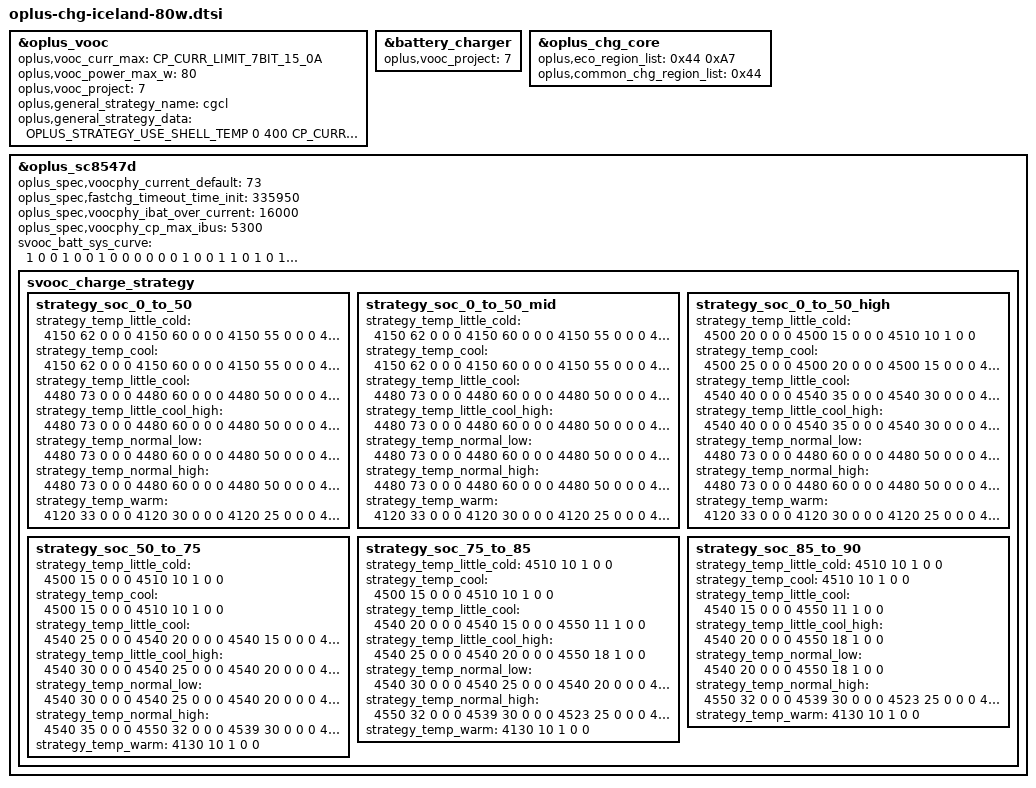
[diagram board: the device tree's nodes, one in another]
&oplus_vooc {
	oplus,vooc_curr_max = <CP_CURR_LIMIT_7BIT_15_0A>;
	oplus,vooc_power_max_w = <80>;
	oplus,vooc_project = <7>;
	oplus,general_strategy_name = "cgcl";
	oplus,general_strategy_data = < OPLUS_STRATEGY_USE_SHELL_TEMP
					0   400 CP_CURR_LIMIT_7BIT_15_0A 1 0
					390 410 CP_CURR_LIMIT_7BIT_7_0A 2 0
					400 420 CP_CURR_LIMIT_7BIT_5_0A 3 1
					410 430 CP_CURR_LIMIT_7BIT_4_0A 4 2
					420 440 CP_CURR_LIMIT_7BIT_3_0A 4 3 >;
};

&battery_charger {
	oplus,vooc_project = <7>;
};

&oplus_chg_core {
	oplus,eco_region_list = /bits/ 8 <0x44 /* EUEX */
					  0xA7 /* ROW */>;
	oplus,common_chg_region_list = /bits/ 8 <0x44 /* EUEX */>;
};

&oplus_sc8547d {
	oplus_spec,voocphy_current_default = <73>;
	oplus_spec,fastchg_timeout_time_init = <335950>;
	oplus_spec,voocphy_ibat_over_current = <16000>;
	oplus_spec,voocphy_cp_max_ibus = <5300>;

	svooc_batt_sys_curve = <1 0 0 1 0 0 1	// 7300mA
				0 0 0 0 0 0 1	// 3414mV
				0 0 1 1 0 1 0	// 2600mA
				1 1 1 1 1 1 0	// 4664mV
				0 0 0 1 0 1 1	// 1100mA
				1 1 1 1 1 1 0>;	// 4664mV

	svooc_charge_strategy {
		strategy_soc_0_to_50 { /* 0 ~ 20 */
			/* 0c ~ 5c */
			strategy_temp_little_cold =	<4150 62 0 0 0
							 4150 60 0 0 0
							 4150 55 0 0 0
							 4150 50 0 0 0
							 4150 45 0 0 0
							 4500 42 0 0 0
							 4500 40 0 0 0
							 4500 35 0 0 0
							 4500 30 0 0 0
							 4500 25 0 0 0
							 4500 20 0 0 0
							 4500 15 0 0 0
							 4510 10 1 0 0>;
			/* 5c ~ 12c */
			strategy_temp_cool =		<4150 62 0 0 0
							 4150 60 0 0 0
							 4150 55 0 0 0
							 4150 50 0 0 0
							 4150 45 0 0 0
							 4500 42 0 0 0
							 4500 40 0 0 0
							 4500 35 0 0 0
							 4500 30 0 0 0
							 4500 25 0 0 0
							 4500 20 0 0 0
							 4500 15 0 0 0
							 4510 10 1 0 0>;
			/* 12c ~ 16c */
			strategy_temp_little_cool =	<4480 73 0 0 0
							 4480 60 0 0 0
							 4480 50 0 0 0
							 4540 49 0 0 0
							 4540 45 0 0 0
							 4540 40 0 0 0
							 4540 35 0 0 0
							 4540 30 0 0 0
							 4540 25 0 0 0
							 4540 20 0 0 0
							 4540 15 0 0 0
							 4550 11 1 0 0>;
			/* 16c ~ 21c */
			strategy_temp_little_cool_high = <4480 73 0 0 0
							  4480 60 0 0 0
							  4480 50 0 0 0
							  4540 49 0 0 0
							  4540 45 0 0 0
							  4540 40 0 0 0
							  4540 35 0 0 0
							  4540 30 0 0 0
							  4540 25 0 0 0
							  4540 20 0 0 0
							  4550 18 1 0 0>;
			/* 21c ~ 35c */
			strategy_temp_normal_low =	<4480 73 0 0 0
							 4480 60 0 0 0
							 4480 50 0 0 0
							 4540 49 0 0 0
							 4540 45 0 0 0
							 4540 40 0 0 0
							 4540 35 0 0 0
							 4540 30 0 0 0
							 4540 25 0 0 0
							 4540 20 0 0 0
							 4550 18 1 0 0>;
			/* 35c ~ 44c */
			strategy_temp_normal_high =	<4480 73 0 0 0
							 4480 60 0 0 0
							 4480 50 0 0 0
							 4540 49 0 0 0
							 4540 45 0 0 0
							 4540 40 0 0 0
							 4540 35 0 0 0
							 4550 32 0 0 0
							 4539 30 0 0 0
							 4523 25 0 0 0
							 4507 20 0 0 0
							 4491 15 0 0 0
							 4475 10 1 0 0>;
			/* 44c ~ 51c */
			strategy_temp_warm =		<4120 33 0 0 0
							 4120 30 0 0 0
							 4120 25 0 0 0
							 4120 20 0 0 0
							 4120 15 0 0 0
							 4130 10 1 0 0>;
		};
		strategy_soc_0_to_50_mid { /* 21 ~ 35 */
			/* 0c ~ 5c */
			strategy_temp_little_cold =	<4150 62 0 0 0
							 4150 60 0 0 0
							 4150 55 0 0 0
							 4150 50 0 0 0
							 4150 45 0 0 0
							 4500 42 0 0 0
							 4500 40 0 0 0
							 4500 35 0 0 0
							 4500 30 0 0 0
							 4500 25 0 0 0
							 4500 20 0 0 0
							 4500 15 0 0 0
							 4510 10 1 0 0>;
			/* 5c ~ 12c */
			strategy_temp_cool =		<4150 62 0 0 0
							 4150 60 0 0 0
							 4150 55 0 0 0
							 4150 50 0 0 0
							 4150 45 0 0 0
							 4500 42 0 0 0
							 4500 40 0 0 0
							 4500 35 0 0 0
							 4500 30 0 0 0
							 4500 25 0 0 0
							 4500 20 0 0 0
							 4500 15 0 0 0
							 4510 10 1 0 0>;
			/* 12c ~ 16c */
			strategy_temp_little_cool =	<4480 73 0 0 0
							 4480 60 0 0 0
							 4480 50 0 0 0
							 4540 49 0 0 0
							 4540 45 0 0 0
							 4540 40 0 0 0
							 4540 35 0 0 0
							 4540 30 0 0 0
							 4540 25 0 0 0
							 4540 20 0 0 0
							 4540 15 0 0 0
							 4550 11 1 0 0>;
			/* 16c ~ 21c */
			strategy_temp_little_cool_high = <4480 73 0 0 0
							  4480 60 0 0 0
							  4480 50 0 0 0
							  4540 49 0 0 0
							  4540 45 0 0 0
							  4540 40 0 0 0
							  4540 35 0 0 0
							  4540 30 0 0 0
							  4540 25 0 0 0
							  4540 20 0 0 0
							  4550 18 1 0 0>;
			/* 21c ~ 35c */
			strategy_temp_normal_low =	<4480 73 0 0 0
							 4480 60 0 0 0
							 4480 50 0 0 0
							 4540 49 0 0 0
							 4540 45 0 0 0
							 4540 40 0 0 0
							 4540 35 0 0 0
							 4540 30 0 0 0
							 4540 25 0 0 0
							 4540 20 0 0 0
							 4550 18 1 0 0>;
			/* 35c ~ 44c */
			strategy_temp_normal_high =	<4480 73 0 0 0
							 4480 60 0 0 0
							 4480 50 0 0 0
							 4540 49 0 0 0
							 4540 45 0 0 0
							 4540 40 0 0 0
							 4540 35 0 0 0
							 4550 32 0 0 0
							 4539 30 0 0 0
							 4523 25 0 0 0
							 4507 20 0 0 0
							 4491 15 0 0 0
							 4475 10 1 0 0>;
			/* 44c ~ 51c */
			strategy_temp_warm =		<4120 33 0 0 0
							 4120 30 0 0 0
							 4120 25 0 0 0
							 4120 20 0 0 0
							 4120 15 0 0 0
							 4130 10 1 0 0>;
		};

		strategy_soc_0_to_50_high { /* 36 ~ 55 */
			/* 0c ~ 5c */
			strategy_temp_little_cold =	<4500 20 0 0 0
							 4500 15 0 0 0
							 4510 10 1 0 0>;
			/* 5c ~ 12c */
			strategy_temp_cool =		<4500 25 0 0 0
							 4500 20 0 0 0
							 4500 15 0 0 0
							 4510 10 1 0 0>;
			/* 12c ~ 16c */
			strategy_temp_little_cool =	<4540 40 0 0 0
							 4540 35 0 0 0
							 4540 30 0 0 0
							 4540 25 0 0 0
							 4540 20 0 0 0
							 4540 15 0 0 0
							 4550 11 1 0 0>;
			/* 16c ~ 21c */
			strategy_temp_little_cool_high = <4540 40 0 0 0
							  4540 35 0 0 0
							  4540 30 0 0 0
							  4540 25 0 0 0
							  4540 20 0 0 0
							  4550 18 1 0 0>;
			/* 21c ~ 35c */
			strategy_temp_normal_low =	<4480 73 0 0 0
							 4480 60 0 0 0
							 4480 50 0 0 0
							 4540 49 0 0 0
							 4540 45 0 0 0
							 4540 40 0 0 0
							 4540 35 0 0 0
							 4540 30 0 0 0
							 4540 25 0 0 0
							 4540 20 0 0 0
							 4550 18 1 0 0>;
			/* 35c ~ 44c */
			strategy_temp_normal_high =	<4480 73 0 0 0
							 4480 60 0 0 0
							 4480 50 0 0 0
							 4540 49 0 0 0
							 4540 45 0 0 0
							 4540 40 0 0 0
							 4540 35 0 0 0
							 4550 32 0 0 0
							 4539 30 0 0 0
							 4523 25 0 0 0
							 4507 20 0 0 0
							 4491 15 0 0 0
							 4475 10 1 0 0>;
			/* 44c ~ 51c */
			strategy_temp_warm =		<4120 33 0 0 0
							 4120 30 0 0 0
							 4120 25 0 0 0
							 4120 20 0 0 0
							 4120 15 0 0 0
							 4130 10 1 0 0>;
		};

		strategy_soc_50_to_75 { /* 56 ~ 75 */
			/* 0c ~ 5c */
			strategy_temp_little_cold =	<4500 15 0 0 0
							 4510 10 1 0 0>;
			/* 5c ~ 12c */
			strategy_temp_cool =		<4500 15 0 0 0
							 4510 10 1 0 0>;
			/* 12c ~ 16c */
			strategy_temp_little_cool =	<4540 25 0 0 0
							 4540 20 0 0 0
							 4540 15 0 0 0
							 4550 11 1 0 0>;
			/* 16c ~ 21c */
			strategy_temp_little_cool_high = <4540 30 0 0 0
							  4540 25 0 0 0
							  4540 20 0 0 0
							  4550 18 1 0 0>;
			/* 21c ~ 35c */
			strategy_temp_normal_low =	<4540 30 0 0 0
							 4540 25 0 0 0
							 4540 20 0 0 0
							 4550 18 1 0 0>;
			/* 35c ~ 44c */
			strategy_temp_normal_high =	<4540 35 0 0 0
							 4550 32 0 0 0
							 4539 30 0 0 0
							 4523 25 0 0 0
							 4507 20 0 0 0
							 4491 15 0 0 0
							 4475 10 1 0 0>;
			/* 44c ~ 51c */
			strategy_temp_warm =		<4130 10 1 0 0>;
		};

		strategy_soc_75_to_85 { /* 76 ~ 85 */
			/* 0c ~ 5c */
			strategy_temp_little_cold =	<4510 10 1 0 0>;
			/* 5c ~ 12c */
			strategy_temp_cool =		<4500 15 0 0 0
							 4510 10 1 0 0>;
			/* 12c ~ 16c */
			strategy_temp_little_cool =	<4540 20 0 0 0
							 4540 15 0 0 0
							 4550 11 1 0 0>;
			/* 16c ~ 21c */
			strategy_temp_little_cool_high = <4540 25 0 0 0
							  4540 20 0 0 0
							  4550 18 1 0 0>;
			/* 21c ~ 35c */
			strategy_temp_normal_low =	<4540 30 0 0 0
							 4540 25 0 0 0
							 4540 20 0 0 0
							 4550 18 1 0 0>;
			/* 35c ~ 44c */
			strategy_temp_normal_high =	<4550 32 0 0 0
							 4539 30 0 0 0
							 4523 25 0 0 0
							 4507 20 0 0 0
							 4491 15 0 0 0
							 4475 10 1 0 0>;
			/* 44c ~ 51c */
			strategy_temp_warm =		<4130 10 1 0 0>;
		};

		strategy_soc_85_to_90 { /* 86 ~ 90 */
			/* 0c ~ 5c */
			strategy_temp_little_cold =	<4510 10 1 0 0>;
			/* 5c ~ 12c */
			strategy_temp_cool =		<4510 10 1 0 0>;
			/* 12c ~ 16c */
			strategy_temp_little_cool =	<4540 15 0 0 0
							 4550 11 1 0 0>;
			/* 16c ~ 21c */
			strategy_temp_little_cool_high = <4540 20 0 0 0
							  4550 18 1 0 0>;
			/* 21c ~ 35c */
			strategy_temp_normal_low =	<4540 20 0 0 0
							 4550 18 1 0 0>;
			/* 35c ~ 44c */
			strategy_temp_normal_high =	<4550 32 0 0 0
							 4539 30 0 0 0
							 4523 25 0 0 0
							 4507 20 0 0 0
							 4491 15 0 0 0
							 4475 10 1 0 0>;
			/* 44c ~ 51c */
			strategy_temp_warm =		<4130 10 1 0 0>;
		};
	};
};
